VERSION "1.0 - vcan telemetry bridge demo"

NS_ :

BS_:

BU_ ECU TESTER

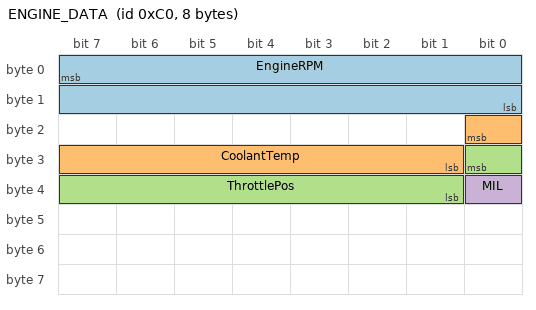
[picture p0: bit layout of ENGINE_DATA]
BO_ 192 ENGINE_DATA: 8 ECU
 SG_ EngineRPM : 7|16@0+ (0.25,0) [0|16383] "rpm" TESTER
 SG_ CoolantTemp : 16|8@0+ (1,-40) [-40|215] "degC" TESTER
 SG_ ThrottlePos : 24|8@0+ (0.4,0) [0|102] "%" TESTER
 SG_ MIL : 32|1@0+ (1,0) [0|1] "" TESTER

BO_ 208 VEHICLE_DATA: 8 ECU
 SG_ VehicleSpeed : 7|16@0+ (0.01,0) [0|655.35] "km/h" TESTER
 SG_ Odometer : 16|24@0+ (1,0) [0|16777215] "m" TESTER

CM_ BO_ 192 "Engine operating data, 10 Hz";
CM_ BO_ 208 "Vehicle motion data, 10 Hz";
CM_ SG_ 192 EngineRPM "Crankshaft speed";
CM_ SG_ 192 CoolantTemp "Engine coolant temperature";
